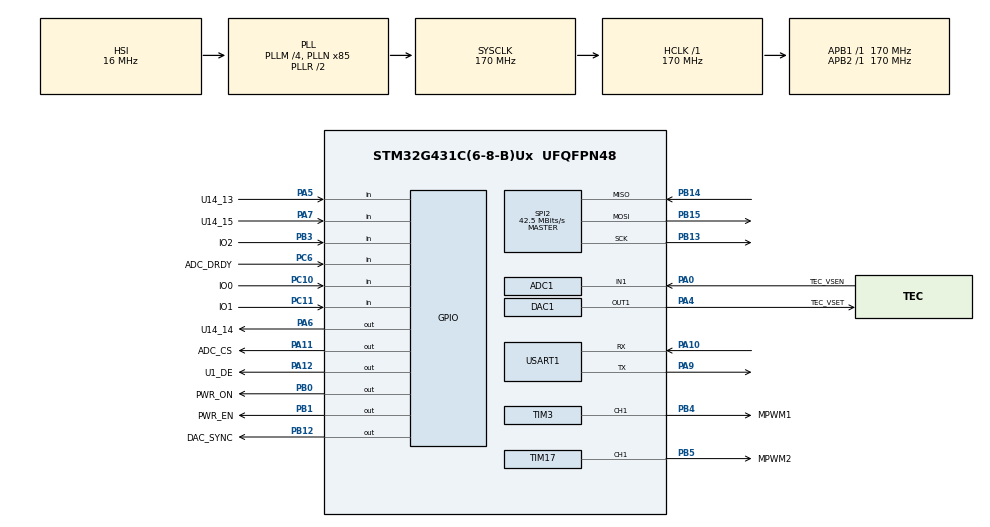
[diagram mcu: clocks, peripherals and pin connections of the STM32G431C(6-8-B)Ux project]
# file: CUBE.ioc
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ADC1.Channel-0\#ChannelRegularConversion=ADC_CHANNEL_1
ADC1.NbrOfConversionFlag=1
ADC1.OffsetNumber-0\#ChannelRegularConversion=ADC_OFFSET_NONE
ADC1.Rank-0\#ChannelRegularConversion=1
ADC1.SamplingTime-0\#ChannelRegularConversion=ADC_SAMPLETIME_47CYCLES_5
ADC1.master=1
DAC1.DAC_Channel-DAC_OUT1_ExtAndInt=DAC_CHANNEL_1
Dma.Request0=USART1_RX
Dma.Request1=USART1_TX
Dma.USART1_RX.0.Direction=DMA_PERIPH_TO_MEMORY
Dma.USART1_RX.0.EventEnable=DISABLE
Dma.USART1_RX.0.Instance=DMA1_Channel1
Dma.USART1_RX.0.MemDataAlignment=DMA_MDATAALIGN_BYTE
Dma.USART1_RX.0.MemInc=DMA_MINC_ENABLE
Dma.USART1_RX.0.Mode=DMA_NORMAL
Dma.USART1_RX.0.PeriphDataAlignment=DMA_PDATAALIGN_BYTE
Dma.USART1_RX.0.PeriphInc=DMA_PINC_DISABLE
Dma.USART1_RX.0.Polarity=HAL_DMAMUX_REQ_GEN_RISING
Dma.USART1_RX.0.Priority=DMA_PRIORITY_LOW
Dma.USART1_RX.0.RequestNumber=1
Dma.USART1_RX.0.SignalID=NONE
Dma.USART1_RX.0.SyncEnable=DISABLE
Dma.USART1_RX.0.SyncPolarity=HAL_DMAMUX_SYNC_NO_EVENT
Dma.USART1_RX.0.SyncRequestNumber=1
Dma.USART1_RX.0.SyncSignalID=NONE
Dma.USART1_TX.1.Direction=DMA_MEMORY_TO_PERIPH
Dma.USART1_TX.1.EventEnable=DISABLE
Dma.USART1_TX.1.Instance=DMA1_Channel2
Dma.USART1_TX.1.MemDataAlignment=DMA_MDATAALIGN_BYTE
Dma.USART1_TX.1.MemInc=DMA_MINC_ENABLE
Dma.USART1_TX.1.Mode=DMA_NORMAL
Dma.USART1_TX.1.PeriphDataAlignment=DMA_PDATAALIGN_BYTE
Dma.USART1_TX.1.PeriphInc=DMA_PINC_DISABLE
Dma.USART1_TX.1.Polarity=HAL_DMAMUX_REQ_GEN_RISING
Dma.USART1_TX.1.Priority=DMA_PRIORITY_LOW
Dma.USART1_TX.1.RequestNumber=1
Dma.USART1_TX.1.SignalID=NONE
Dma.USART1_TX.1.SyncEnable=DISABLE
Dma.USART1_TX.1.SyncPolarity=HAL_DMAMUX_SYNC_NO_EVENT
Dma.USART1_TX.1.SyncRequestNumber=1
Dma.USART1_TX.1.SyncSignalID=NONE
Mcu.Family=STM32G4
Mcu.Name=STM32G431C(6-8-B)Ux
Mcu.Package=UFQFPN48
NVIC.DMA1_Channel1_IRQn=true\:0\:0\:false\:false\:true\:false\:true\:true
NVIC.DMA1_Channel2_IRQn=true\:0\:0\:false\:false\:true\:false\:true\:true
NVIC.PriorityGroup=NVIC_PRIORITYGROUP_4
PA0.GPIO_Label=TEC_VSEN
PA0.Mode=IN1-Single-Ended
PA0.Signal=ADC1_IN1
PA1.GPIO_Label=TEC_PWMN
PA1.Signal=TIM15_CH1N
PA10.Mode=Asynchronous
PA10.Signal=USART1_RX
PA11.GPIO_Label=ADC_CS
PA11.GPIO_PuPd=GPIO_PULLUP
PA11.Signal=GPIO_Output
PA12.GPIO_Label=U1_DE
PA12.GPIO_PuPd=GPIO_PULLDOWN
PA12.Signal=GPIO_Output
PA13.Mode=Serial_Wire
PA13.Signal=SYS_JTMS-SWDIO
PA14.Mode=Serial_Wire
PA14.Signal=SYS_JTCK-SWCLK
PA2.GPIO_Label=TEC_PWM
PA2.Signal=S_TIM15_CH1
PA4.GPIO_Label=TEC_VSET
PA4.Signal=COMP_DAC11_group
PA5.GPIO_Label=U14_13
PA5.Signal=GPIO_Input
PA6.GPIO_Label=U14_14
PA6.GPIO_PuPd=GPIO_PULLDOWN
PA6.Signal=GPIO_Output
PA7.GPIO_Label=U14_15
PA7.Signal=GPIO_Input
PA9.Mode=Asynchronous
PA9.Signal=USART1_TX
PB0.GPIO_Label=PWR_ON
PB0.GPIO_PuPd=GPIO_PULLDOWN
PB0.GPIO_Speed=GPIO_SPEED_FREQ_MEDIUM
PB0.PinState=GPIO_PIN_SET
PB0.Signal=GPIO_Output
PB1.GPIO_Label=PWR_EN
PB1.GPIO_PuPd=GPIO_PULLDOWN
PB1.Signal=GPIO_Output
PB12.GPIO_Label=DAC_SYNC
PB12.GPIO_PuPd=GPIO_PULLUP
PB12.PinState=GPIO_PIN_SET
PB12.Signal=GPIO_Output
PB13.Mode=Full_Duplex_Master
PB13.Signal=SPI2_SCK
PB14.Mode=Full_Duplex_Master
PB14.Signal=SPI2_MISO
PB15.Mode=Full_Duplex_Master
PB15.Signal=SPI2_MOSI
PB3.GPIO_Label=IO2
PB3.Signal=GPIO_Input
PB4.GPIO_Label=MPWM1
PB4.Signal=S_TIM3_CH1
PB5.GPIO_Label=MPWM2
PB5.Signal=S_TIM17_CH1
PC10.GPIO_Label=IO0
PC10.Signal=GPIO_Input
PC11.GPIO_Label=IO1
PC11.Signal=GPIO_Input
PC6.GPIO_Label=ADC_DRDY
PC6.Signal=GPIO_Input
ProjectManager.HeapSize=0x200
ProjectManager.StackSize=0x400
ProjectManager.TargetToolchain=Makefile
RCC.ADC12Freq_Value=170000000
RCC.AHBFreq_Value=170000000
RCC.APB1Freq_Value=170000000
RCC.APB1TimFreq_Value=170000000
RCC.APB2Freq_Value=170000000
RCC.APB2TimFreq_Value=170000000
RCC.CortexFreq_Value=170000000
RCC.EXTERNAL_CLOCK_VALUE=12288000
RCC.HCLKFreq_Value=170000000
RCC.HSE_VALUE=8000000
RCC.HSI48_VALUE=48000000
RCC.HSI_VALUE=16000000
RCC.LSE_VALUE=32768
RCC.PLLM=RCC_PLLM_DIV4
RCC.PLLN=85
RCC.SYSCLKFreq_VALUE=170000000
RCC.SYSCLKSource=RCC_SYSCLKSOURCE_PLLCLK
RCC.USBFreq_Value=170000000
RCC.VCOOutputFreq_Value=340000000
SH.COMP_DAC11_group.0=DAC1_OUT1,DAC_OUT1_ExtAndInt
SH.S_TIM15_CH1.0=TIM15_CH1
SH.S_TIM17_CH1.0=TIM17_CH1,PWM Generation1 CH1
SH.S_TIM3_CH1.0=TIM3_CH1,PWM Generation1 CH1
SPI2.BaudRatePrescaler=SPI_BAUDRATEPRESCALER_4
SPI2.CalculateBaudRate=42.5 MBits/s
SPI2.Direction=SPI_DIRECTION_2LINES
SPI2.Mode=SPI_MODE_MASTER
SPI2.VirtualType=VM_MASTER
TIM15.Channel-PWM\ Generation1\ CH1=TIM_CHANNEL_1
TIM17.Channel=TIM_CHANNEL_1
TIM3.Channel-PWM\ Generation1\ CH1=TIM_CHANNEL_1
USART1.VirtualMode-Asynchronous=VM_ASYNC
VP_SYS_VS_DBSignals.Mode=DisableDeadBatterySignals
VP_TIM17_VS_ClockSourceINT.Mode=Enable_Timer
board=custom

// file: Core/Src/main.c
/* USER CODE BEGIN Header */
/**
  ******************************************************************************
  * @file           : main.c
  * @brief          : Main program body
  ******************************************************************************
  * @attention
  *
  * Copyright (c) 2026 STMicroelectronics.
  * All rights reserved.
  *
  * This software is licensed under terms that can be found in the LICENSE file
  * in the root directory of this software component.
  * If no LICENSE file comes with this software, it is provided AS-IS.
  *
  ******************************************************************************
  */
/* USER CODE END Header */
#include "main.h"
#include "adc.h"
#include "dac.h"
#include "dma.h"
#include "spi.h"
#include "tim.h"
#include "usart.h"
#include "gpio.h"

/* USER CODE BEGIN Includes */
#include "tec_hw.h"

/* USER CODE END Includes */

void SystemClock_Config(void);

int main(void)
{

  /* MCU Configuration--------------------------------------------------------*/

  /* Reset of all peripherals, Initializes the Flash interface and the Systick. */
  HAL_Init();

  /* Configure the system clock */
  SystemClock_Config();

  /* Initialize all configured peripherals */
  MX_GPIO_Init();
  MX_DMA_Init();
  MX_ADC1_Init();
  MX_DAC1_Init();
  MX_SPI2_Init();
  MX_TIM3_Init();
  MX_TIM15_Init();
  MX_TIM17_Init();
  MX_USART1_UART_Init();
  /* USER CODE BEGIN 2 */
  TEC_HW_Init();
#if (TEC_BRINGUP_ENABLE_ON_BOOT != 0U)
  if (TEC_HW_GetState() == TEC_HW_STATE_READY)
  {
    TEC_HW_SetVsetMv(TEC_BRINGUP_VSET_MV);
    TEC_HW_EnableOutput();
    TEC_HW_SetPwmCommand(TEC_BRINGUP_PWM_CMD_PERMILLE);
  }
#endif

  /* USER CODE END 2 */

  /* Infinite loop */
  while (1)
  {

  }
}

void SystemClock_Config(void)
{
  RCC_OscInitTypeDef RCC_OscInitStruct = {0};
  RCC_ClkInitTypeDef RCC_ClkInitStruct = {0};

  /** Configure the main internal regulator output voltage
  */
  HAL_PWREx_ControlVoltageScaling(PWR_REGULATOR_VOLTAGE_SCALE1_BOOST);

  /** Initializes the RCC Oscillators according to the specified parameters
  * in the RCC_OscInitTypeDef structure.
  */
  RCC_OscInitStruct.OscillatorType = RCC_OSCILLATORTYPE_HSI;
  RCC_OscInitStruct.HSIState = RCC_HSI_ON;
  RCC_OscInitStruct.HSICalibrationValue = RCC_HSICALIBRATION_DEFAULT;
  RCC_OscInitStruct.PLL.PLLState = RCC_PLL_ON;
  RCC_OscInitStruct.PLL.PLLSource = RCC_PLLSOURCE_HSI;
  RCC_OscInitStruct.PLL.PLLM = RCC_PLLM_DIV4;
  RCC_OscInitStruct.PLL.PLLN = 85;
  RCC_OscInitStruct.PLL.PLLP = RCC_PLLP_DIV2;
  RCC_OscInitStruct.PLL.PLLQ = RCC_PLLQ_DIV2;
  RCC_OscInitStruct.PLL.PLLR = RCC_PLLR_DIV2;
  if (HAL_RCC_OscConfig(&RCC_OscInitStruct) != HAL_OK)
  {
    Error_Handler();
  }

  /** Initializes the CPU, AHB and APB buses clocks
  */
  RCC_ClkInitStruct.ClockType = RCC_CLOCKTYPE_HCLK|RCC_CLOCKTYPE_SYSCLK
                              |RCC_CLOCKTYPE_PCLK1|RCC_CLOCKTYPE_PCLK2;
  RCC_ClkInitStruct.SYSCLKSource = RCC_SYSCLKSOURCE_PLLCLK;
  RCC_ClkInitStruct.AHBCLKDivider = RCC_SYSCLK_DIV1;
  RCC_ClkInitStruct.APB1CLKDivider = RCC_HCLK_DIV1;
  RCC_ClkInitStruct.APB2CLKDivider = RCC_HCLK_DIV1;

  if (HAL_RCC_ClockConfig(&RCC_ClkInitStruct, FLASH_LATENCY_4) != HAL_OK)
  {
    Error_Handler();
  }
}

void Error_Handler(void)
{
  __disable_irq();
  while (1)
  {
  }
}
